AUTOSAR XML (schema 4-1-1)
package /E2E_InterSWC_2
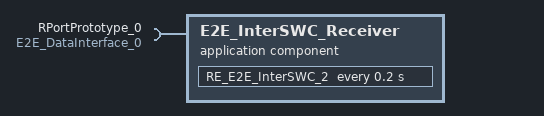
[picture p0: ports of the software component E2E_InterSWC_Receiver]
  application sw component type E2E_InterSWC_Receiver
    require port RPortPrototype_0: required-interface=E2E_DataInterface_0
    behavior IB_E2E_InterSWC_2
      timing event E2E_InterSWC_2_Event: start-on-event=RE_E2E_InterSWC_2, period=0.2
      runnable RE_E2E_InterSWC_2: symbol=E2E_InterSWC_2_REProc
        data-receive-point-by-arguments:
          access DRPA_CKS_0: accessed-variable=RPortPrototype_0.CKS
          access DRPA_Alive_Cnt_0: accessed-variable=RPortPrototype_0.Alive_Cnt
          access DRPA_Data_0: accessed-variable=RPortPrototype_0.Data
